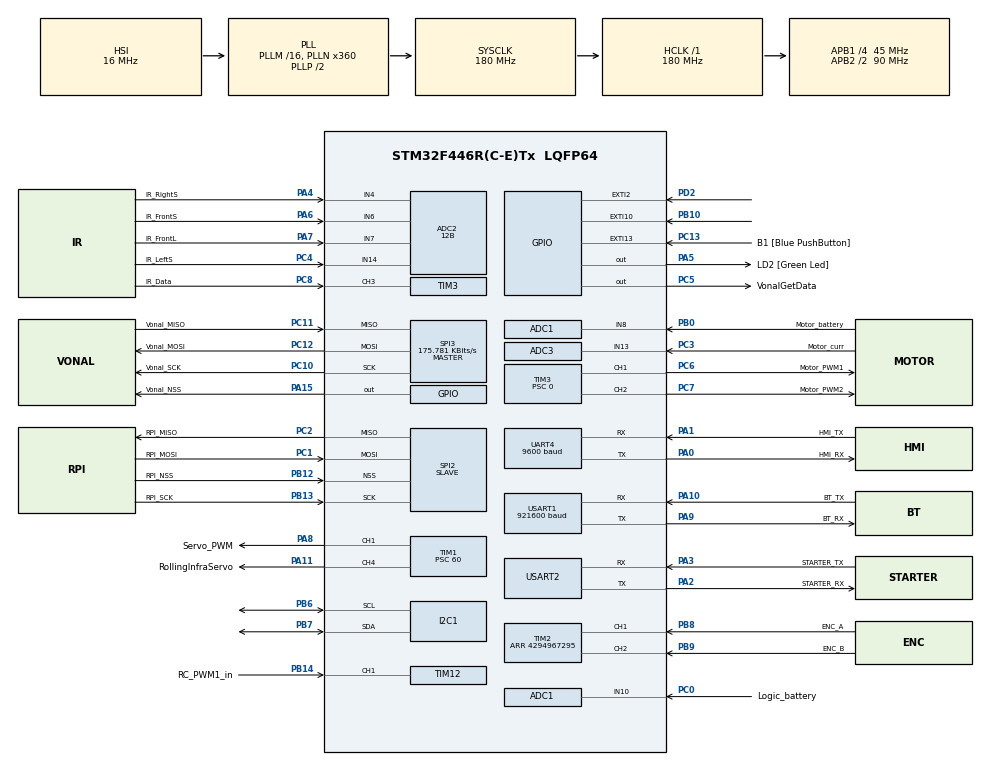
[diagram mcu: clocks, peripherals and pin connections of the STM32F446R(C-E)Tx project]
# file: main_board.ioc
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ADC1.Channel-0\#ChannelRegularConversion=ADC_CHANNEL_8
ADC1.Channel-1\#ChannelRegularConversion=ADC_CHANNEL_10
ADC1.Channel-2\#ChannelRegularConversion=ADC_CHANNEL_TEMPSENSOR
ADC1.ClockPrescaler=ADC_CLOCK_SYNC_PCLK_DIV8
ADC1.ContinuousConvMode=DISABLE
ADC1.DMAContinuousRequests=ENABLE
ADC1.DataAlign=ADC_DATAALIGN_RIGHT
ADC1.DiscontinuousConvMode=DISABLE
ADC1.EOCSelection=ADC_EOC_SINGLE_CONV
ADC1.EnableAnalogWatchDog=false
ADC1.ExternalTrigConv=ADC_SOFTWARE_START
ADC1.ExternalTrigConvEdge=ADC_EXTERNALTRIGCONVEDGE_NONE
ADC1.InjNumberOfConversion=0
ADC1.NbrOfConversion=3
ADC1.NbrOfConversionFlag=1
ADC1.Rank-0\#ChannelRegularConversion=1
ADC1.Rank-1\#ChannelRegularConversion=2
ADC1.Rank-2\#ChannelRegularConversion=3
ADC1.Resolution=ADC_RESOLUTION_12B
ADC1.SamplingTime-0\#ChannelRegularConversion=ADC_SAMPLETIME_480CYCLES
ADC1.SamplingTime-1\#ChannelRegularConversion=ADC_SAMPLETIME_480CYCLES
ADC1.SamplingTime-2\#ChannelRegularConversion=ADC_SAMPLETIME_480CYCLES
ADC1.ScanConvMode=ENABLE
ADC1.master=1
ADC2.Channel-0\#ChannelRegularConversion=ADC_CHANNEL_4
ADC2.Channel-1\#ChannelRegularConversion=ADC_CHANNEL_4
ADC2.Channel-2\#ChannelRegularConversion=ADC_CHANNEL_4
ADC2.Channel-3\#ChannelRegularConversion=ADC_CHANNEL_4
ADC2.Channel-4\#ChannelRegularConversion=ADC_CHANNEL_6
ADC2.Channel-5\#ChannelRegularConversion=ADC_CHANNEL_7
ADC2.Channel-6\#ChannelRegularConversion=ADC_CHANNEL_14
ADC2.ClockPrescaler=ADC_CLOCK_SYNC_PCLK_DIV8
ADC2.ContinuousConvMode=DISABLE
ADC2.DMAContinuousRequests=ENABLE
ADC2.DataAlign=ADC_DATAALIGN_RIGHT
ADC2.DiscontinuousConvMode=DISABLE
ADC2.EOCSelection=ADC_EOC_SINGLE_CONV
ADC2.EnableAnalogWatchDog=false
ADC2.ExternalTrigConv=ADC_SOFTWARE_START
ADC2.ExternalTrigConvEdge=ADC_EXTERNALTRIGCONVEDGE_NONE
ADC2.InjNumberOfConversion=0
ADC2.NbrOfConversion=4
ADC2.NbrOfConversionFlag=1
ADC2.Rank-0\#ChannelRegularConversion=1
ADC2.Rank-1\#ChannelRegularConversion=2
ADC2.Rank-2\#ChannelRegularConversion=3
ADC2.Rank-3\#ChannelRegularConversion=4
ADC2.Rank-4\#ChannelRegularConversion=2
ADC2.Rank-5\#ChannelRegularConversion=3
ADC2.Rank-6\#ChannelRegularConversion=4
ADC2.Resolution=ADC_RESOLUTION_12B
ADC2.SamplingTime-0\#ChannelRegularConversion=ADC_SAMPLETIME_480CYCLES
ADC2.SamplingTime-1\#ChannelRegularConversion=ADC_SAMPLETIME_3CYCLES
ADC2.SamplingTime-2\#ChannelRegularConversion=ADC_SAMPLETIME_3CYCLES
ADC2.SamplingTime-3\#ChannelRegularConversion=ADC_SAMPLETIME_3CYCLES
ADC2.SamplingTime-4\#ChannelRegularConversion=ADC_SAMPLETIME_480CYCLES
ADC2.SamplingTime-5\#ChannelRegularConversion=ADC_SAMPLETIME_480CYCLES
ADC2.SamplingTime-6\#ChannelRegularConversion=ADC_SAMPLETIME_480CYCLES
ADC2.ScanConvMode=ENABLE
ADC3.Channel-65\#ChannelRegularConversion=ADC_CHANNEL_13
ADC3.ClockPrescaler=ADC_CLOCK_SYNC_PCLK_DIV8
ADC3.ContinuousConvMode=DISABLE
ADC3.DMAContinuousRequests=ENABLE
ADC3.DataAlign=ADC_DATAALIGN_RIGHT
ADC3.DiscontinuousConvMode=DISABLE
ADC3.EOCSelection=ADC_EOC_SINGLE_CONV
ADC3.EnableAnalogWatchDog=false
ADC3.ExternalTrigConv=ADC_SOFTWARE_START
ADC3.ExternalTrigConvEdge=ADC_EXTERNALTRIGCONVEDGE_NONE
ADC3.InjNumberOfConversion=0
ADC3.NbrOfConversion=1
ADC3.NbrOfConversionFlag=1
ADC3.Rank-65\#ChannelRegularConversion=1
ADC3.Resolution=ADC_RESOLUTION_12B
ADC3.SamplingTime-65\#ChannelRegularConversion=ADC_SAMPLETIME_480CYCLES
ADC3.ScanConvMode=ENABLE
Dma.ADC1.11.Direction=DMA_PERIPH_TO_MEMORY
Dma.ADC1.11.FIFOMode=DMA_FIFOMODE_DISABLE
Dma.ADC1.11.Instance=DMA2_Stream0
Dma.ADC1.11.MemDataAlignment=DMA_MDATAALIGN_HALFWORD
Dma.ADC1.11.MemInc=DMA_MINC_ENABLE
Dma.ADC1.11.Mode=DMA_NORMAL
Dma.ADC1.11.PeriphDataAlignment=DMA_PDATAALIGN_HALFWORD
Dma.ADC1.11.PeriphInc=DMA_PINC_DISABLE
Dma.ADC1.11.Priority=DMA_PRIORITY_LOW
Dma.ADC2.4.Direction=DMA_PERIPH_TO_MEMORY
Dma.ADC2.4.FIFOMode=DMA_FIFOMODE_DISABLE
Dma.ADC2.4.Instance=DMA2_Stream2
Dma.ADC2.4.MemDataAlignment=DMA_MDATAALIGN_HALFWORD
Dma.ADC2.4.MemInc=DMA_MINC_ENABLE
Dma.ADC2.4.Mode=DMA_NORMAL
Dma.ADC2.4.PeriphDataAlignment=DMA_PDATAALIGN_HALFWORD
Dma.ADC2.4.PeriphInc=DMA_PINC_DISABLE
Dma.ADC2.4.Priority=DMA_PRIORITY_MEDIUM
Dma.ADC3.3.Direction=DMA_PERIPH_TO_MEMORY
Dma.ADC3.3.FIFOMode=DMA_FIFOMODE_DISABLE
Dma.ADC3.3.Instance=DMA2_Stream1
Dma.ADC3.3.MemDataAlignment=DMA_MDATAALIGN_HALFWORD
Dma.ADC3.3.MemInc=DMA_MINC_ENABLE
Dma.ADC3.3.Mode=DMA_NORMAL
Dma.ADC3.3.PeriphDataAlignment=DMA_PDATAALIGN_HALFWORD
Dma.ADC3.3.PeriphInc=DMA_PINC_DISABLE
Dma.ADC3.3.Priority=DMA_PRIORITY_HIGH
Dma.I2C1_RX.7.Direction=DMA_PERIPH_TO_MEMORY
Dma.I2C1_RX.7.FIFOMode=DMA_FIFOMODE_DISABLE
Dma.I2C1_RX.7.Instance=DMA1_Stream0
Dma.I2C1_RX.7.MemDataAlignment=DMA_MDATAALIGN_BYTE
Dma.I2C1_RX.7.MemInc=DMA_MINC_ENABLE
Dma.I2C1_RX.7.Mode=DMA_NORMAL
Dma.I2C1_RX.7.PeriphDataAlignment=DMA_PDATAALIGN_BYTE
Dma.I2C1_RX.7.PeriphInc=DMA_PINC_DISABLE
Dma.I2C1_RX.7.Priority=DMA_PRIORITY_LOW
Dma.I2C1_TX.8.Direction=DMA_MEMORY_TO_PERIPH
Dma.I2C1_TX.8.FIFOMode=DMA_FIFOMODE_DISABLE
Dma.I2C1_TX.8.Instance=DMA1_Stream6
Dma.I2C1_TX.8.MemDataAlignment=DMA_MDATAALIGN_BYTE
Dma.I2C1_TX.8.MemInc=DMA_MINC_ENABLE
Dma.I2C1_TX.8.Mode=DMA_NORMAL
Dma.I2C1_TX.8.PeriphDataAlignment=DMA_PDATAALIGN_BYTE
Dma.I2C1_TX.8.PeriphInc=DMA_PINC_DISABLE
Dma.I2C1_TX.8.Priority=DMA_PRIORITY_LOW
Dma.Request0=USART1_RX
Dma.Request1=USART1_TX
Dma.Request10=TIM3_CH1/TRIG
Dma.Request11=ADC1
Dma.Request12=SPI2_RX
Dma.Request2=TIM1_CH1
Dma.Request3=ADC3
Dma.Request4=ADC2
Dma.Request5=SPI3_RX
Dma.Request6=SPI3_TX
Dma.Request7=I2C1_RX
Dma.Request8=I2C1_TX
Dma.Request9=TIM3_CH2
Dma.SPI2_RX.12.Direction=DMA_PERIPH_TO_MEMORY
Dma.SPI2_RX.12.FIFOMode=DMA_FIFOMODE_ENABLE
Dma.SPI2_RX.12.FIFOThreshold=DMA_FIFO_THRESHOLD_3QUARTERSFULL
Dma.SPI2_RX.12.Instance=DMA1_Stream3
Dma.SPI2_RX.12.MemBurst=DMA_MBURST_SINGLE
Dma.SPI2_RX.12.MemDataAlignment=DMA_MDATAALIGN_BYTE
Dma.SPI2_RX.12.MemInc=DMA_MINC_ENABLE
Dma.SPI2_RX.12.Mode=DMA_NORMAL
Dma.SPI2_RX.12.PeriphBurst=DMA_PBURST_SINGLE
Dma.SPI2_RX.12.PeriphDataAlignment=DMA_PDATAALIGN_BYTE
Dma.SPI2_RX.12.PeriphInc=DMA_PINC_DISABLE
Dma.SPI2_RX.12.Priority=DMA_PRIORITY_LOW
Dma.SPI3_RX.5.Direction=DMA_PERIPH_TO_MEMORY
Dma.SPI3_RX.5.FIFOMode=DMA_FIFOMODE_DISABLE
Dma.SPI3_RX.5.Instance=DMA1_Stream2
Dma.SPI3_RX.5.MemDataAlignment=DMA_MDATAALIGN_BYTE
Dma.SPI3_RX.5.MemInc=DMA_MINC_ENABLE
Dma.SPI3_RX.5.Mode=DMA_NORMAL
Dma.SPI3_RX.5.PeriphDataAlignment=DMA_PDATAALIGN_BYTE
Dma.SPI3_RX.5.PeriphInc=DMA_PINC_DISABLE
Dma.SPI3_RX.5.Priority=DMA_PRIORITY_LOW
Dma.SPI3_TX.6.Direction=DMA_MEMORY_TO_PERIPH
Dma.SPI3_TX.6.FIFOMode=DMA_FIFOMODE_DISABLE
Dma.SPI3_TX.6.Instance=DMA1_Stream7
Dma.SPI3_TX.6.MemDataAlignment=DMA_MDATAALIGN_BYTE
Dma.SPI3_TX.6.MemInc=DMA_MINC_ENABLE
Dma.SPI3_TX.6.Mode=DMA_NORMAL
Dma.SPI3_TX.6.PeriphDataAlignment=DMA_PDATAALIGN_BYTE
Dma.SPI3_TX.6.PeriphInc=DMA_PINC_DISABLE
Dma.SPI3_TX.6.Priority=DMA_PRIORITY_LOW
Dma.TIM1_CH1.2.Direction=DMA_PERIPH_TO_MEMORY
Dma.TIM1_CH1.2.FIFOMode=DMA_FIFOMODE_DISABLE
Dma.TIM1_CH1.2.Instance=DMA2_Stream3
Dma.TIM1_CH1.2.MemDataAlignment=DMA_MDATAALIGN_HALFWORD
Dma.TIM1_CH1.2.MemInc=DMA_MINC_DISABLE
Dma.TIM1_CH1.2.Mode=DMA_NORMAL
Dma.TIM1_CH1.2.PeriphDataAlignment=DMA_PDATAALIGN_HALFWORD
Dma.TIM1_CH1.2.PeriphInc=DMA_PINC_DISABLE
Dma.TIM1_CH1.2.Priority=DMA_PRIORITY_LOW
Dma.TIM3_CH1/TRIG.10.Direction=DMA_PERIPH_TO_MEMORY
Dma.TIM3_CH1/TRIG.10.FIFOMode=DMA_FIFOMODE_DISABLE
Dma.TIM3_CH1/TRIG.10.Instance=DMA1_Stream4
Dma.TIM3_CH1/TRIG.10.MemDataAlignment=DMA_MDATAALIGN_HALFWORD
Dma.TIM3_CH1/TRIG.10.MemInc=DMA_MINC_ENABLE
Dma.TIM3_CH1/TRIG.10.Mode=DMA_NORMAL
Dma.TIM3_CH1/TRIG.10.PeriphDataAlignment=DMA_PDATAALIGN_HALFWORD
Dma.TIM3_CH1/TRIG.10.PeriphInc=DMA_PINC_DISABLE
Dma.TIM3_CH1/TRIG.10.Priority=DMA_PRIORITY_LOW
Dma.TIM3_CH2.9.Direction=DMA_PERIPH_TO_MEMORY
Dma.TIM3_CH2.9.FIFOMode=DMA_FIFOMODE_DISABLE
Dma.TIM3_CH2.9.Instance=DMA1_Stream5
Dma.TIM3_CH2.9.MemDataAlignment=DMA_MDATAALIGN_HALFWORD
Dma.TIM3_CH2.9.MemInc=DMA_MINC_ENABLE
Dma.TIM3_CH2.9.Mode=DMA_NORMAL
Dma.TIM3_CH2.9.PeriphDataAlignment=DMA_PDATAALIGN_HALFWORD
Dma.TIM3_CH2.9.PeriphInc=DMA_PINC_DISABLE
Dma.TIM3_CH2.9.Priority=DMA_PRIORITY_LOW
Dma.USART1_RX.0.Direction=DMA_PERIPH_TO_MEMORY
Dma.USART1_RX.0.FIFOMode=DMA_FIFOMODE_DISABLE
Dma.USART1_RX.0.Instance=DMA2_Stream5
Dma.USART1_RX.0.MemDataAlignment=DMA_MDATAALIGN_BYTE
Dma.USART1_RX.0.MemInc=DMA_MINC_ENABLE
Dma.USART1_RX.0.Mode=DMA_NORMAL
Dma.USART1_RX.0.PeriphDataAlignment=DMA_PDATAALIGN_BYTE
Dma.USART1_RX.0.PeriphInc=DMA_PINC_DISABLE
Dma.USART1_RX.0.Priority=DMA_PRIORITY_HIGH
Dma.USART1_TX.1.Direction=DMA_MEMORY_TO_PERIPH
Dma.USART1_TX.1.FIFOMode=DMA_FIFOMODE_DISABLE
Dma.USART1_TX.1.Instance=DMA2_Stream7
Dma.USART1_TX.1.MemDataAlignment=DMA_MDATAALIGN_BYTE
Dma.USART1_TX.1.MemInc=DMA_MINC_ENABLE
Dma.USART1_TX.1.Mode=DMA_NORMAL
Dma.USART1_TX.1.PeriphDataAlignment=DMA_PDATAALIGN_BYTE
Dma.USART1_TX.1.PeriphInc=DMA_PINC_DISABLE
Dma.USART1_TX.1.Priority=DMA_PRIORITY_HIGH
FREERTOS.INCLUDE_xEventGroupSetBitFromISR=1
FREERTOS.INCLUDE_xTimerPendFunctionCall=1
FREERTOS.Tasks01=defaultTask,0,128,StartDefaultTask,Default,NULL
FREERTOS.configTOTAL_HEAP_SIZE=100000
FREERTOS.configUSE_TIMERS=1
Mcu.Family=STM32F4
Mcu.Name=STM32F446R(C-E)Tx
Mcu.Package=LQFP64
NVIC.ADC_IRQn=true\:5\:0\:false\:false\:true\:true\:true
NVIC.DMA1_Stream0_IRQn=true\:5\:0\:false\:false\:true\:true\:false
NVIC.DMA1_Stream2_IRQn=true\:5\:0\:false\:false\:true\:false\:false
NVIC.DMA1_Stream3_IRQn=true\:5\:0\:false\:false\:true\:true\:false
NVIC.DMA1_Stream4_IRQn=true\:5\:0\:false\:false\:true\:true\:false
NVIC.DMA1_Stream5_IRQn=true\:5\:0\:false\:false\:true\:true\:false
NVIC.DMA1_Stream6_IRQn=true\:5\:0\:false\:false\:true\:true\:false
NVIC.DMA1_Stream7_IRQn=true\:5\:0\:false\:false\:true\:true\:false
NVIC.DMA2_Stream0_IRQn=true\:5\:0\:false\:false\:true\:true\:false
NVIC.DMA2_Stream1_IRQn=true\:5\:0\:false\:false\:true\:true\:false
NVIC.DMA2_Stream2_IRQn=true\:5\:0\:false\:false\:true\:true\:false
NVIC.DMA2_Stream3_IRQn=true\:5\:0\:false\:false\:true\:true\:false
NVIC.DMA2_Stream5_IRQn=true\:5\:0\:false\:false\:true\:true\:false
NVIC.DMA2_Stream7_IRQn=true\:5\:0\:false\:false\:true\:true\:false
NVIC.EXTI15_10_IRQn=true\:5\:0\:false\:false\:true\:true\:true
NVIC.EXTI2_IRQn=true\:5\:0\:false\:false\:true\:true\:true
NVIC.I2C1_ER_IRQn=true\:5\:0\:false\:false\:true\:true\:true
NVIC.I2C1_EV_IRQn=true\:5\:0\:false\:false\:true\:true\:true
NVIC.PriorityGroup=NVIC_PRIORITYGROUP_4
NVIC.SPI2_IRQn=true\:5\:0\:false\:false\:true\:true\:true
NVIC.SPI3_IRQn=true\:5\:0\:false\:false\:true\:true\:true
NVIC.TIM8_BRK_TIM12_IRQn=true\:5\:0\:false\:false\:true\:true\:true
NVIC.TIM8_TRG_COM_TIM14_IRQn=true\:0\:0\:false\:false\:true\:false\:true
NVIC.TimeBase=TIM8_TRG_COM_TIM14_IRQn
NVIC.TimeBaseIP=TIM14
NVIC.UART4_IRQn=true\:5\:0\:false\:false\:true\:true\:true
NVIC.USART1_IRQn=true\:5\:0\:false\:false\:true\:true\:true
NVIC.USART2_IRQn=true\:5\:0\:false\:false\:true\:true\:true
PA0-WKUP.GPIO_Label=HMI_RX
PA0-WKUP.Mode=Asynchronous
PA0-WKUP.Signal=UART4_TX
PA1.GPIO_Label=HMI_TX
PA1.Mode=Asynchronous
PA1.Signal=UART4_RX
PA10.GPIO_Label=BT_TX
PA10.Mode=Asynchronous
PA10.Signal=USART1_RX
PA11.GPIO_Label=RollingInfraServo
PA11.Signal=S_TIM1_CH4
PA13.GPIO_Label=TMS
PA13.Signal=SYS_JTMS-SWDIO
PA14.GPIO_Label=TCK
PA14.Signal=SYS_JTCK-SWCLK
PA15.GPIO_Label=Vonal_NSS
PA15.GPIO_Speed=GPIO_SPEED_FREQ_VERY_HIGH
PA15.PinState=GPIO_PIN_SET
PA15.Signal=GPIO_Output
PA2.GPIO_Label=STARTER_RX
PA2.Mode=Asynchronous
PA2.Signal=USART2_TX
PA3.GPIO_Label=STARTER_TX
PA3.Mode=Asynchronous
PA3.Signal=USART2_RX
PA4.GPIO_Label=IR_RightS
PA4.Signal=ADCx_IN4
PA5.GPIO_Label=LD2 [Green Led]
PA5.Signal=GPIO_Output
PA6.GPIO_Label=IR_FrontS
PA6.Signal=ADCx_IN6
PA7.GPIO_Label=IR_FrontL
PA7.Signal=ADCx_IN7
PA8.GPIO_Label=Servo_PWM
PA8.GPIO_Speed=GPIO_SPEED_FREQ_HIGH
PA8.Signal=S_TIM1_CH1
PA9.GPIO_Label=BT_RX
PA9.Mode=Asynchronous
PA9.Signal=USART1_TX
PB0.GPIO_Label=Motor_battery
PB0.Signal=ADCx_IN8
PB10.Signal=GPXTI10
PB12.GPIO_Label=RPI_NSS
PB12.Mode=NSS_Signal_Hard_Input
PB12.Signal=SPI2_NSS
PB13.GPIO_Label=RPI_SCK
PB13.Mode=Full_Duplex_Slave
PB13.Signal=SPI2_SCK
PB14.GPIO_Label=RC_PWM1_in
PB14.Signal=S_TIM12_CH1
PB3.GPIO_Label=SWO
PB3.Signal=SYS_JTDO-SWO
PB6.Mode=I2C
PB6.Signal=I2C1_SCL
PB7.Mode=I2C
PB7.Signal=I2C1_SDA
PB8.GPIO_Label=ENC_A
PB8.GPIO_PuPd=GPIO_NOPULL
PB8.Signal=S_TIM2_CH1_ETR
PB9.GPIO_Label=ENC_B
PB9.GPIO_PuPd=GPIO_NOPULL
PB9.Signal=S_TIM2_CH2
PC0.GPIO_Label=Logic_battery
PC0.Signal=ADCx_IN10
PC1.GPIO_Label=RPI_MOSI
PC1.Mode=Full_Duplex_Slave
PC1.Signal=SPI2_MOSI
PC10.GPIO_Label=Vonal_SCK
PC10.GPIO_PuPd=GPIO_PULLDOWN
PC10.Mode=Full_Duplex_Master
PC10.Signal=SPI3_SCK
PC11.GPIO_Label=Vonal_MISO
PC11.Mode=Full_Duplex_Master
PC11.Signal=SPI3_MISO
PC12.GPIO_Label=Vonal_MOSI
PC12.Mode=Full_Duplex_Master
PC12.Signal=SPI3_MOSI
PC13.GPIO_Label=B1 [Blue PushButton]
PC13.GPIO_ModeDefaultEXTI=GPIO_MODE_IT_FALLING
PC13.Signal=GPXTI13
PC14-OSC32_IN.Signal=RCC_OSC32_IN
PC15-OSC32_OUT.Signal=RCC_OSC32_OUT
PC2.GPIO_Label=RPI_MISO
PC2.Mode=Full_Duplex_Slave
PC2.Signal=SPI2_MISO
PC3.GPIO_Label=Motor_curr
PC3.Signal=ADCx_IN13
PC4.GPIO_Label=IR_LeftS
PC4.Signal=ADCx_IN14
PC5.GPIO_Label=VonalGetData
PC5.Signal=GPIO_Output
PC6.GPIO_Label=Motor_PWM1
PC6.Signal=S_TIM3_CH1
PC7.GPIO_Label=Motor_PWM2
PC7.Signal=S_TIM3_CH2
PC8.GPIO_Label=IR_Data
PC8.Signal=S_TIM3_CH3
PD2.Signal=GPXTI2
PH0-OSC_IN.Signal=RCC_OSC_IN
PH1-OSC_OUT.Signal=RCC_OSC_OUT
ProjectManager.HeapSize=0x200
ProjectManager.StackSize=0x400
ProjectManager.TargetToolchain=TrueSTUDIO
RCC.AHBFreq_Value=180000000
RCC.APB1CLKDivider=RCC_HCLK_DIV4
RCC.APB1Freq_Value=45000000
RCC.APB1TimFreq_Value=90000000
RCC.APB2CLKDivider=RCC_HCLK_DIV2
RCC.APB2Freq_Value=90000000
RCC.APB2TimFreq_Value=180000000
RCC.CortexFreq_Value=180000000
RCC.FLatency-AdvancedSettings=FLASH_LATENCY_5
RCC.HCLKFreq_Value=180000000
RCC.HSE_VALUE=8000000
RCC.HSI_VALUE=16000000
RCC.LSE_VALUE=32768
RCC.PLLN=360
RCC.SYSCLKFreq_VALUE=180000000
RCC.SYSCLKSource=RCC_SYSCLKSOURCE_PLLCLK
RCC.USBFreq_Value=180000000
RCC.VCOOutputFreq_Value=360000000
SH.ADCx_IN10.0=ADC1_IN10,IN10
SH.ADCx_IN13.0=ADC3_IN13,IN13
SH.ADCx_IN14.0=ADC2_IN14,IN14
SH.ADCx_IN4.0=ADC2_IN4,IN4
SH.ADCx_IN6.0=ADC2_IN6,IN6
SH.ADCx_IN7.0=ADC2_IN7,IN7
SH.ADCx_IN8.0=ADC1_IN8,IN8
SH.S_TIM12_CH1.0=TIM12_CH1,PWM_Input_1
SH.S_TIM1_CH1.0=TIM1_CH1,PWM Generation1 CH1
SH.S_TIM1_CH4.0=TIM1_CH4,PWM Generation4 CH4
SH.S_TIM2_CH1_ETR.0=TIM2_CH1,Encoder_Interface
SH.S_TIM2_CH2.0=TIM2_CH2,Encoder_Interface
SH.S_TIM3_CH1.0=TIM3_CH1,PWM Generation1 CH1
SH.S_TIM3_CH2.0=TIM3_CH2,PWM Generation2 CH2
SH.S_TIM3_CH3.0=TIM3_CH3,Input_Capture3_from_TI3
SPI2.Direction=SPI_DIRECTION_2LINES
SPI2.Mode=SPI_MODE_SLAVE
SPI2.VirtualNSS=VM_NSSHARD
SPI2.VirtualType=VM_SLAVE
SPI3.BaudRatePrescaler=SPI_BAUDRATEPRESCALER_256
SPI3.CLKPhase=SPI_PHASE_1EDGE
SPI3.CalculateBaudRate=175.781 KBits/s
SPI3.Direction=SPI_DIRECTION_2LINES
SPI3.Mode=SPI_MODE_MASTER
SPI3.VirtualType=VM_MASTER
TIM1.Channel-PWM\ Generation1\ CH1=TIM_CHANNEL_1
TIM1.Channel-PWM\ Generation4\ CH4=TIM_CHANNEL_4
TIM1.ClockDivision=TIM_CLOCKDIVISION_DIV1
TIM1.CounterMode=TIM_COUNTERMODE_DOWN
TIM1.OCIdleState_1=TIM_OCIDLESTATE_RESET
TIM1.OCMode_PWM-PWM\ Generation1\ CH1=TIM_OCMODE_PWM1
TIM1.OCPolarity_1=TIM_OCPOLARITY_HIGH
TIM1.Period=60000
TIM1.Prescaler=60
TIM1.Pulse-PWM\ Generation1\ CH1=4180
TIM1.Pulse-PWM\ Generation4\ CH4=4180
TIM12.Period=65535
TIM12.Prescaler=100
TIM2.ClockDivision=TIM_CLOCKDIVISION_DIV1
TIM2.EncoderMode=TIM_ENCODERMODE_TI12
TIM2.IC1Polarity=TIM_ICPOLARITY_FALLING
TIM2.IC2Polarity=TIM_ICPOLARITY_RISING
TIM2.Period=4294967295
TIM3.Channel-Input_Capture3_from_TI3=TIM_CHANNEL_3
TIM3.Channel-PWM\ Generation1\ CH1=TIM_CHANNEL_1
TIM3.Channel-PWM\ Generation2\ CH2=TIM_CHANNEL_2
TIM3.CounterMode=TIM_COUNTERMODE_CENTERALIGNED1
TIM3.OCPolarity_2=TIM_OCPOLARITY_HIGH
TIM3.Period=4500
TIM3.Prescaler=0
TIM3.Pulse-PWM\ Generation1\ CH1=2250
TIM3.Pulse-PWM\ Generation2\ CH2=2250
UART4.BaudRate=9600
UART4.VirtualMode=Asynchronous
USART1.BaudRate=921600
USART1.VirtualMode=VM_ASYNC
USART2.VirtualMode=VM_ASYNC
VP_ADC1_TempSens_Input.Mode=IN-TempSens
VP_FREERTOS_VS_ENABLE.Mode=Enabled
VP_SYS_VS_tim14.Mode=TIM14
VP_TIM10_VS_ClockSourceINT.Mode=Enable_Timer
VP_TIM1_VS_ClockSourceINT.Mode=Internal
VP_TIM7_VS_ClockSourceINT.Mode=Enable_Timer
board=NUCLEO-F446RE

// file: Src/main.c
/**
  ******************************************************************************
  * File Name          : main.c
  * Description        : Main program body
  ******************************************************************************
  * This notice applies to any and all portions of this file
  * that are not between comment pairs USER CODE BEGIN and
  * USER CODE END. Other portions of this file, whether
  * inserted by the user or by software development tools
  * are owned by their respective copyright owners.
  *
  * Copyright (c) 2018 STMicroelectronics International N.V.
  * All rights reserved.
  *
  * Redistribution and use in source and binary forms, with or without
  * modification, are permitted, provided that the following conditions are met:
  *
  * 1. Redistribution of source code must retain the above copyright notice,
  *    this list of conditions and the following disclaimer.
  * 2. Redistributions in binary form must reproduce the above copyright notice,
  *    this list of conditions and the following disclaimer in the documentation
  *    and/or other materials provided with the distribution.
  * 3. Neither the name of STMicroelectronics nor the names of other
  *    contributors to this software may be used to endorse or promote products
  *    derived from this software without specific written permission.
  * 4. This software, including modifications and/or derivative works of this
  *    software, must execute solely and exclusively on microcontroller or
  *    microprocessor devices manufactured by or for STMicroelectronics.
  * 5. Redistribution and use of this software other than as permitted under
  *    this license is void and will automatically terminate your rights under
  *    this license.
  *
  * THIS SOFTWARE IS PROVIDED BY STMICROELECTRONICS AND CONTRIBUTORS "AS IS"
  * AND ANY EXPRESS, IMPLIED OR STATUTORY WARRANTIES, INCLUDING, BUT NOT
  * LIMITED TO, THE IMPLIED WARRANTIES OF MERCHANTABILITY, FITNESS FOR A
  * PARTICULAR PURPOSE AND NON-INFRINGEMENT OF THIRD PARTY INTELLECTUAL PROPERTY
  * RIGHTS ARE DISCLAIMED TO THE FULLEST EXTENT PERMITTED BY LAW. IN NO EVENT
  * SHALL STMICROELECTRONICS OR CONTRIBUTORS BE LIABLE FOR ANY DIRECT, INDIRECT,
  * INCIDENTAL, SPECIAL, EXEMPLARY, OR CONSEQUENTIAL DAMAGES (INCLUDING, BUT NOT
  * LIMITED TO, PROCUREMENT OF SUBSTITUTE GOODS OR SERVICES; LOSS OF USE, DATA,
  * OR PROFITS; OR BUSINESS INTERRUPTION) HOWEVER CAUSED AND ON ANY THEORY OF
  * LIABILITY, WHETHER IN CONTRACT, STRICT LIABILITY, OR TORT (INCLUDING
  * NEGLIGENCE OR OTHERWISE) ARISING IN ANY WAY OUT OF THE USE OF THIS SOFTWARE,
  * EVEN IF ADVISED OF THE POSSIBILITY OF SUCH DAMAGE.
  *
  ******************************************************************************
  */

#include "main.h"
#include "stm32f4xx_hal.h"
#include "cmsis_os.h"

/* USER CODE BEGIN Includes */

#include "register_map.h"
#include "bluetooth.h"
#include "hmi.h"
#include "ir.h"
#include "line_sensor.h"
#include "mpu6050.h"
#include "starter.h"
#include "string.h"
#include "controller.h"
#include "remotecontrol.h"
#include "statemachine.h"
#include "rpi.h"

/* USER CODE END Includes */

ADC_HandleTypeDef hadc1;
ADC_HandleTypeDef hadc2;
ADC_HandleTypeDef hadc3;
DMA_HandleTypeDef hdma_adc1;
DMA_HandleTypeDef hdma_adc2;
DMA_HandleTypeDef hdma_adc3;

I2C_HandleTypeDef hi2c1;
DMA_HandleTypeDef hdma_i2c1_rx;
DMA_HandleTypeDef hdma_i2c1_tx;

SPI_HandleTypeDef hspi2;
SPI_HandleTypeDef hspi3;
DMA_HandleTypeDef hdma_spi2_rx;
DMA_HandleTypeDef hdma_spi3_rx;
DMA_HandleTypeDef hdma_spi3_tx;

TIM_HandleTypeDef htim1;
TIM_HandleTypeDef htim2;
TIM_HandleTypeDef htim3;
TIM_HandleTypeDef htim7;
TIM_HandleTypeDef htim10;
TIM_HandleTypeDef htim12;
DMA_HandleTypeDef hdma_tim1_ch1;
DMA_HandleTypeDef hdma_tim3_ch2;
DMA_HandleTypeDef hdma_tim3_ch1_trig;

UART_HandleTypeDef huart4;
UART_HandleTypeDef huart1;
UART_HandleTypeDef huart2;
DMA_HandleTypeDef hdma_usart1_rx;
DMA_HandleTypeDef hdma_usart1_tx;

osThreadId defaultTaskHandle;

/* USER CODE BEGIN PV */
/* Private variables ---------------------------------------------------------*/

osThreadId SendBTTaskHandle;
osThreadId LineDataTaskHandle;
osThreadId InitTaskHandle;
osThreadId DetectTaskHandle;
osThreadId ControllerTaskHandle;
osThreadId RemotecontrolTaskHandle;
osThreadId CheckBatteriesTaskHandle;
osThreadId ReadDistanceSensorsTaskHandle;
osThreadId ReadMotorCurrentTaskHandle;
osThreadId InfraReceiveTaskHandle;
osThreadId ReadMEMSTaskHandle;
osThreadId StateMachineTaskHandle;
osThreadId SpeedControllerTaskHandle;
osThreadId UthosszTaskHandle;
osThreadId SteeringStateSpaceControllerHandle;
osThreadId ServoSetterTaskHandle;
osThreadId LineDetectorTaskHandle;
osThreadId RollAngleControllerTaskHandle;
osThreadId CarTrackerTaskHandle;
osThreadId HMITaskHandle;

SemaphoreHandle_t Semaphore_linesensor_ready;
SemaphoreHandle_t Semaphore_SPI_vonal_buffer;
SemaphoreHandle_t Semaphore_ADC_batteries;
SemaphoreHandle_t Semaphore_ADC_dist_sensors;
SemaphoreHandle_t Semaphore_ADC_motor_curr;
SemaphoreHandle_t Semaphore_MEMS_ready;
SemaphoreHandle_t Semaphore_Uthossz_Achieved;
EventGroupHandle_t Eventgroup_inputCaptures;
EventGroupHandle_t Eventgroup_Triggers;
TimerHandle_t xTimers[NUM_OF_TIMERS];

/* USER CODE END PV */

void SystemClock_Config(void);
static void MX_GPIO_Init(void);
static void MX_DMA_Init(void);
static void MX_ADC1_Init(void);
static void MX_ADC2_Init(void);
static void MX_ADC3_Init(void);
static void MX_SPI2_Init(void);
static void MX_SPI3_Init(void);
static void MX_TIM1_Init(void);
static void MX_TIM2_Init(void);
static void MX_TIM3_Init(void);
static void MX_TIM10_Init(void);
static void MX_TIM12_Init(void);
static void MX_UART4_Init(void);
static void MX_USART1_UART_Init(void);
static void MX_USART2_UART_Init(void);
static void MX_TIM7_Init(void);
static void MX_I2C1_Init(void);
void StartDefaultTask(void const * argument);

void HAL_TIM_MspPostInit(TIM_HandleTypeDef *htim);

/* USER CODE BEGIN PFP */
/* Private function prototypes -----------------------------------------------*/

void BTCommunicationTask(void const * argument);
void LineGetData(void const * argument);
void InitTask(void const * argument);
void DetectTask(void const * argument);
void CheckBatteriesTask(void const * argument);
void ReadDistanceSensorsTask(void const * argument);
void ReadMotorCurrentTask(void const * argument);
void InfraReceiveTask(void const * argument);
void ReadMEMSTask(void const * argument);
void StateMachineTask(void const * argument);
void SpeedControllerTask (void const * argument);
void UthosszTask(void const * argument);
void SteeringStateSpaceController(void const * argument);
void PIDController(void const * argument);
void ServoSetterTask(void const * argument);
void LineDetectorTask(void const * argument);
void RollAngleControllerTask(void const * argument);
void CarTrackerTask();
void HMITask();

/* USER CODE END PFP */

int main(void)
{

  /* USER CODE BEGIN 1 */
	InitRegisters();
  /* USER CODE END 1 */

  /* MCU Configuration----------------------------------------------------------*/

  /* Reset of all peripherals, Initializes the Flash interface and the Systick. */
  HAL_Init();

  /* Configure the system clock */
  SystemClock_Config();

  /* Initialize all configured peripherals */
  MX_GPIO_Init();
  MX_DMA_Init();
  MX_ADC1_Init();
  MX_ADC2_Init();
  MX_ADC3_Init();
  MX_SPI2_Init();
  MX_SPI3_Init();
  MX_TIM1_Init();
  MX_TIM2_Init();
  MX_TIM3_Init();
  MX_TIM10_Init();
  MX_TIM12_Init();
  MX_UART4_Init();
  MX_USART1_UART_Init();
  MX_USART2_UART_Init();
  MX_TIM7_Init();
  MX_I2C1_Init();

  /* Create the thread(s) */
  /* definition and creation of defaultTask */
  osThreadDef(defaultTask, StartDefaultTask, osPriorityNormal, 0, 128);
  defaultTaskHandle = osThreadCreate(osThread(defaultTask), NULL);

  /* USER CODE BEGIN RTOS_THREADS */
  /* add threads, ... */
  osThreadDef(BTCom, BTCommunicationTask, osPriorityBelowNormal, 0, 512);
  SendBTTaskHandle = osThreadCreate(osThread(BTCom), NULL);

  osThreadDef(Init, InitTask, osPriorityNormal, 0, 128);
  InitTaskHandle = osThreadCreate(osThread(Init), NULL);

  osThreadDef(LineDataTask, LineGetData, osPriorityHigh, 0, 512);
  LineDataTaskHandle = osThreadCreate(osThread(LineDataTask), NULL);

  osThreadDef(ControllerTask, PIDController, osPriorityNormal, 0, 512);
  ControllerTaskHandle = osThreadCreate(osThread(ControllerTask), NULL);

  osThreadDef(DetectTask, DetectTask, osPriorityNormal, 0, 512);
  DetectTaskHandle = osThreadCreate(osThread(DetectTask), NULL);

  osThreadDef(RemotecontrolTask, RemoteControllerTask, osPriorityLow, 0, 128);
  RemotecontrolTaskHandle = osThreadCreate(osThread(RemotecontrolTask), NULL);

  osThreadDef(CheckBatteriesTask, CheckBatteriesTask, osPriorityLow, 0, 128);
  CheckBatteriesTaskHandle = osThreadCreate(osThread(CheckBatteriesTask), NULL);

  osThreadDef(ReadDistanceSensorsTask, ReadDistanceSensorsTask, osPriorityBelowNormal, 0, 512);
  ReadDistanceSensorsTaskHandle = osThreadCreate(osThread(ReadDistanceSensorsTask), NULL);

  osThreadDef(ReadMotorCurrentTask, ReadMotorCurrentTask, osPriorityLow, 0, 128);
  ReadMotorCurrentTaskHandle = osThreadCreate(osThread(ReadMotorCurrentTask), NULL);

  osThreadDef(InfraReceiveTask, InfraReceiveTask, osPriorityBelowNormal, 0, 256);
  InfraReceiveTaskHandle = osThreadCreate(osThread(InfraReceiveTask), NULL);

  //osThreadDef(ReadMEMSTask, ReadMEMSTask, osPriorityNormal, 0, 512);
  //ReadMEMSTaskHandle = osThreadCreate(osThread(ReadMEMSTask), NULL);

  osThreadDef(StateMachineTask, StateMachineTask, osPriorityNormal, 0, 512);
  StateMachineTaskHandle = osThreadCreate(osThread(StateMachineTask), NULL);

  osThreadDef(SpeedControllerTask, SpeedControllerTask, osPriorityAboveNormal, 0, 512);
  SpeedControllerTaskHandle = osThreadCreate(osThread(SpeedControllerTask), NULL);

  osThreadDef(UthosszTask, UthosszTask, osPriorityNormal, 0, 256);
  UthosszTaskHandle = osThreadCreate(osThread(UthosszTask), NULL);

  osThreadDef(SteeringStateSpaceController, SteeringStateSpaceController, osPriorityHigh, 0, 256);
  SteeringStateSpaceControllerHandle = osThreadCreate(osThread(SteeringStateSpaceController), NULL);

  osThreadDef(ServoSetterTask, ServoSetterTask, osPriorityHigh, 0, 128);
  ServoSetterTaskHandle = osThreadCreate(osThread(ServoSetterTask), NULL);

  osThreadDef(LineDetectorTask, LineDetectorTask, osPriorityAboveNormal, 0, 128);
  LineDetectorTaskHandle = osThreadCreate(osThread(LineDetectorTask), NULL);

  osThreadDef(RollAngleControllerTask, RollAngleControllerTask, osPriorityAboveNormal, 0, 128);
  RollAngleControllerTaskHandle = osThreadCreate(osThread(RollAngleControllerTask), NULL);

  osThreadDef(CarTrackerTask, CarTrackerTask, osPriorityAboveNormal, 0, 128);
  CarTrackerTaskHandle = osThreadCreate(osThread(CarTrackerTask), NULL);

  osThreadDef(HMITask, HMITask, osPriorityAboveNormal, 0, 128);
  HMITaskHandle = osThreadCreate(osThread(HMITask), NULL);

  osThreadSuspend(ServoSetterTaskHandle);
  osThreadSuspend(LineDataTaskHandle );
  osThreadSuspend(SendBTTaskHandle);
  osThreadSuspend(DetectTaskHandle);
  osThreadSuspend(defaultTaskHandle);
  osThreadSuspend(RemotecontrolTaskHandle);
  osThreadSuspend(CheckBatteriesTaskHandle);
  osThreadSuspend(ReadDistanceSensorsTaskHandle);
  osThreadSuspend(ReadMotorCurrentTaskHandle);
  osThreadSuspend(InfraReceiveTaskHandle);
  osThreadSuspend(ReadMEMSTaskHandle);
  osThreadSuspend(StateMachineTaskHandle);
  osThreadSuspend(SpeedControllerTaskHandle);
  osThreadSuspend(UthosszTaskHandle);
  osThreadSuspend(SteeringStateSpaceControllerHandle);
  osThreadSuspend(ControllerTaskHandle);
  osThreadSuspend(LineDetectorTaskHandle);
  osThreadSuspend(RollAngleControllerTaskHandle);
  osThreadSuspend(CarTrackerTaskHandle);
  osThreadSuspend(HMITaskHandle);

  InitTimers();

  /* USER CODE END RTOS_THREADS */

  /* Start scheduler */
  osKernelStart();

  /* We should never get here as control is now taken by the scheduler */

  /* Infinite loop */
  while (1)
  {

  }

}

/** System Clock Configuration
*/
void SystemClock_Config(void)
{

  RCC_OscInitTypeDef RCC_OscInitStruct;
  RCC_ClkInitTypeDef RCC_ClkInitStruct;

    /**Configure the main internal regulator output voltage
    */
  __HAL_RCC_PWR_CLK_ENABLE();

  __HAL_PWR_VOLTAGESCALING_CONFIG(PWR_REGULATOR_VOLTAGE_SCALE1);

    /**Initializes the CPU, AHB and APB busses clocks
    */
  RCC_OscInitStruct.OscillatorType = RCC_OSCILLATORTYPE_HSI;
  RCC_OscInitStruct.HSIState = RCC_HSI_ON;
  RCC_OscInitStruct.HSICalibrationValue = 16;
  RCC_OscInitStruct.PLL.PLLState = RCC_PLL_ON;
  RCC_OscInitStruct.PLL.PLLSource = RCC_PLLSOURCE_HSI;
  RCC_OscInitStruct.PLL.PLLM = 16;
  RCC_OscInitStruct.PLL.PLLN = 360;
  RCC_OscInitStruct.PLL.PLLP = RCC_PLLP_DIV2;
  RCC_OscInitStruct.PLL.PLLQ = 2;
  RCC_OscInitStruct.PLL.PLLR = 2;
  if (HAL_RCC_OscConfig(&RCC_OscInitStruct) != HAL_OK)
  {
    _Error_Handler(__FILE__, __LINE__);
  }

    /**Activate the Over-Drive mode
    */
  if (HAL_PWREx_EnableOverDrive() != HAL_OK)
  {
    _Error_Handler(__FILE__, __LINE__);
  }

    /**Initializes the CPU, AHB and APB busses clocks
    */
  RCC_ClkInitStruct.ClockType = RCC_CLOCKTYPE_HCLK|RCC_CLOCKTYPE_SYSCLK
                              |RCC_CLOCKTYPE_PCLK1|RCC_CLOCKTYPE_PCLK2;
  RCC_ClkInitStruct.SYSCLKSource = RCC_SYSCLKSOURCE_PLLCLK;
  RCC_ClkInitStruct.AHBCLKDivider = RCC_SYSCLK_DIV1;
  RCC_ClkInitStruct.APB1CLKDivider = RCC_HCLK_DIV4;
  RCC_ClkInitStruct.APB2CLKDivider = RCC_HCLK_DIV2;

  if (HAL_RCC_ClockConfig(&RCC_ClkInitStruct, FLASH_LATENCY_5) != HAL_OK)
  {
    _Error_Handler(__FILE__, __LINE__);
  }

    /**Configure the Systick interrupt time
    */
  HAL_SYSTICK_Config(HAL_RCC_GetHCLKFreq()/1000);

    /**Configure the Systick
    */
  HAL_SYSTICK_CLKSourceConfig(SYSTICK_CLKSOURCE_HCLK);

  /* SysTick_IRQn interrupt configuration */
  HAL_NVIC_SetPriority(SysTick_IRQn, 15, 0);
}

/* ADC1 init function */
static void MX_ADC1_Init(void)
{

  ADC_ChannelConfTypeDef sConfig;

    /**Configure the global features of the ADC (Clock, Resolution, Data Alignment and number of conversion)
    */
  hadc1.Instance = ADC1;
  hadc1.Init.ClockPrescaler = ADC_CLOCK_SYNC_PCLK_DIV8;
  hadc1.Init.Resolution = ADC_RESOLUTION_12B;
  hadc1.Init.ScanConvMode = ENABLE;
  hadc1.Init.ContinuousConvMode = DISABLE;
  hadc1.Init.DiscontinuousConvMode = DISABLE;
  hadc1.Init.ExternalTrigConvEdge = ADC_EXTERNALTRIGCONVEDGE_NONE;
  hadc1.Init.ExternalTrigConv = ADC_SOFTWARE_START;
  hadc1.Init.DataAlign = ADC_DATAALIGN_RIGHT;
  hadc1.Init.NbrOfConversion = 3;
  hadc1.Init.DMAContinuousRequests = ENABLE;
  hadc1.Init.EOCSelection = ADC_EOC_SINGLE_CONV;
  if (HAL_ADC_Init(&hadc1) != HAL_OK)
  {
    _Error_Handler(__FILE__, __LINE__);
  }

    /**Configure for the selected ADC regular channel its corresponding rank in the sequencer and its sample time.
    */
  sConfig.Channel = ADC_CHANNEL_8;
  sConfig.Rank = 1;
  sConfig.SamplingTime = ADC_SAMPLETIME_480CYCLES;
  if (HAL_ADC_ConfigChannel(&hadc1, &sConfig) != HAL_OK)
  {
    _Error_Handler(__FILE__, __LINE__);
  }

    /**Configure for the selected ADC regular channel its corresponding rank in the sequencer and its sample time.
    */
  sConfig.Channel = ADC_CHANNEL_10;
  sConfig.Rank = 2;
  if (HAL_ADC_ConfigChannel(&hadc1, &sConfig) != HAL_OK)
  {
    _Error_Handler(__FILE__, __LINE__);
  }

    /**Configure for the selected ADC regular channel its corresponding rank in the sequencer and its sample time.
    */
  sConfig.Channel = ADC_CHANNEL_TEMPSENSOR;
  sConfig.Rank = 3;
  if (HAL_ADC_ConfigChannel(&hadc1, &sConfig) != HAL_OK)
  {
    _Error_Handler(__FILE__, __LINE__);
  }

}

/* ADC2 init function */
static void MX_ADC2_Init(void)
{

  ADC_ChannelConfTypeDef sConfig;

    /**Configure the global features of the ADC (Clock, Resolution, Data Alignment and number of conversion)
    */
  hadc2.Instance = ADC2;
  hadc2.Init.ClockPrescaler = ADC_CLOCK_SYNC_PCLK_DIV8;
  hadc2.Init.Resolution = ADC_RESOLUTION_12B;
  hadc2.Init.ScanConvMode = ENABLE;
  hadc2.Init.ContinuousConvMode = DISABLE;
  hadc2.Init.DiscontinuousConvMode = DISABLE;
  hadc2.Init.ExternalTrigConvEdge = ADC_EXTERNALTRIGCONVEDGE_NONE;
  hadc2.Init.ExternalTrigConv = ADC_SOFTWARE_START;
  hadc2.Init.DataAlign = ADC_DATAALIGN_RIGHT;
  hadc2.Init.NbrOfConversion = 4;
  hadc2.Init.DMAContinuousRequests = ENABLE;
  hadc2.Init.EOCSelection = ADC_EOC_SINGLE_CONV;
  if (HAL_ADC_Init(&hadc2) != HAL_OK)
  {
    _Error_Handler(__FILE__, __LINE__);
  }

    /**Configure for the selected ADC regular channel its corresponding rank in the sequencer and its sample time.
    */
  sConfig.Channel = ADC_CHANNEL_4;
  sConfig.Rank = 1;
  sConfig.SamplingTime = ADC_SAMPLETIME_480CYCLES;
  if (HAL_ADC_ConfigChannel(&hadc2, &sConfig) != HAL_OK)
  {
    _Error_Handler(__FILE__, __LINE__);
  }

    /**Configure for the selected ADC regular channel its corresponding rank in the sequencer and its sample time.
    */
  sConfig.Rank = 2;
  sConfig.SamplingTime = ADC_SAMPLETIME_3CYCLES;
  if (HAL_ADC_ConfigChannel(&hadc2, &sConfig) != HAL_OK)
  {
    _Error_Handler(__FILE__, __LINE__);
  }

    /**Configure for the selected ADC regular channel its corresponding rank in the sequencer and its sample time.
    */
  sConfig.Rank = 3;
  if (HAL_ADC_ConfigChannel(&hadc2, &sConfig) != HAL_OK)
  {
    _Error_Handler(__FILE__, __LINE__);
  }

    /**Configure for the selected ADC regular channel its corresponding rank in the sequencer and its sample time.
    */
  sConfig.Rank = 4;
  if (HAL_ADC_ConfigChannel(&hadc2, &sConfig) != HAL_OK)
  {
    _Error_Handler(__FILE__, __LINE__);
  }

    /**Configure for the selected ADC regular channel its corresponding rank in the sequencer and its sample time.
    */
  sConfig.Channel = ADC_CHANNEL_6;
  sConfig.Rank = 2;
  sConfig.SamplingTime = ADC_SAMPLETIME_480CYCLES;
  if (HAL_ADC_ConfigChannel(&hadc2, &sConfig) != HAL_OK)
  {
    _Error_Handler(__FILE__, __LINE__);
  }

    /**Configure for the selected ADC regular channel its corresponding rank in the sequencer and its sample time.
    */
  sConfig.Channel = ADC_CHANNEL_7;
  sConfig.Rank = 3;
  if (HAL_ADC_ConfigChannel(&hadc2, &sConfig) != HAL_OK)
  {
    _Error_Handler(__FILE__, __LINE__);
  }

    /**Configure for the selected ADC regular channel its corresponding rank in the sequencer and its sample time.
    */
  sConfig.Channel = ADC_CHANNEL_14;
  sConfig.Rank = 4;
  if (HAL_ADC_ConfigChannel(&hadc2, &sConfig) != HAL_OK)
  {
    _Error_Handler(__FILE__, __LINE__);
  }

}

/* ADC3 init function */
static void MX_ADC3_Init(void)
{

  ADC_ChannelConfTypeDef sConfig;

    /**Configure the global features of the ADC (Clock, Resolution, Data Alignment and number of conversion)
    */
  hadc3.Instance = ADC3;
  hadc3.Init.ClockPrescaler = ADC_CLOCK_SYNC_PCLK_DIV8;
  hadc3.Init.Resolution = ADC_RESOLUTION_12B;
  hadc3.Init.ScanConvMode = ENABLE;
  hadc3.Init.ContinuousConvMode = DISABLE;
  hadc3.Init.DiscontinuousConvMode = DISABLE;
  hadc3.Init.ExternalTrigConvEdge = ADC_EXTERNALTRIGCONVEDGE_NONE;
  hadc3.Init.ExternalTrigConv = ADC_SOFTWARE_START;
  hadc3.Init.DataAlign = ADC_DATAALIGN_RIGHT;
  hadc3.Init.NbrOfConversion = 1;
  hadc3.Init.DMAContinuousRequests = ENABLE;
  hadc3.Init.EOCSelection = ADC_EOC_SINGLE_CONV;
  if (HAL_ADC_Init(&hadc3) != HAL_OK)
  {
    _Error_Handler(__FILE__, __LINE__);
  }

    /**Configure for the selected ADC regular channel its corresponding rank in the sequencer and its sample time.
    */
  sConfig.Channel = ADC_CHANNEL_13;
  sConfig.Rank = 1;
  sConfig.SamplingTime = ADC_SAMPLETIME_480CYCLES;
  if (HAL_ADC_ConfigChannel(&hadc3, &sConfig) != HAL_OK)
  {
    _Error_Handler(__FILE__, __LINE__);
  }

}

/* I2C1 init function */
static void MX_I2C1_Init(void)
{

  hi2c1.Instance = I2C1;
  hi2c1.Init.ClockSpeed = 100000;
  hi2c1.Init.DutyCycle = I2C_DUTYCYCLE_2;
  hi2c1.Init.OwnAddress1 = 0;
  hi2c1.Init.AddressingMode = I2C_ADDRESSINGMODE_7BIT;
  hi2c1.Init.DualAddressMode = I2C_DUALADDRESS_DISABLE;
  hi2c1.Init.OwnAddress2 = 0;
  hi2c1.Init.GeneralCallMode = I2C_GENERALCALL_DISABLE;
  hi2c1.Init.NoStretchMode = I2C_NOSTRETCH_DISABLE;
  if (HAL_I2C_Init(&hi2c1) != HAL_OK)
  {
    _Error_Handler(__FILE__, __LINE__);
  }

}

/* SPI2 init function */
static void MX_SPI2_Init(void)
{

  /* SPI2 parameter configuration*/
  hspi2.Instance = SPI2;
  hspi2.Init.Mode = SPI_MODE_SLAVE;
  hspi2.Init.Direction = SPI_DIRECTION_2LINES;
  hspi2.Init.DataSize = SPI_DATASIZE_8BIT;
  hspi2.Init.CLKPolarity = SPI_POLARITY_LOW;
  hspi2.Init.CLKPhase = SPI_PHASE_1EDGE;
  hspi2.Init.NSS = SPI_NSS_HARD_INPUT;
  hspi2.Init.FirstBit = SPI_FIRSTBIT_MSB;
  hspi2.Init.TIMode = SPI_TIMODE_DISABLE;
  hspi2.Init.CRCCalculation = SPI_CRCCALCULATION_DISABLE;
  hspi2.Init.CRCPolynomial = 10;
  if (HAL_SPI_Init(&hspi2) != HAL_OK)
  {
    _Error_Handler(__FILE__, __LINE__);
  }

}

/* SPI3 init function */
static void MX_SPI3_Init(void)
{

  /* SPI3 parameter configuration*/
  hspi3.Instance = SPI3;
  hspi3.Init.Mode = SPI_MODE_MASTER;
  hspi3.Init.Direction = SPI_DIRECTION_2LINES;
  hspi3.Init.DataSize = SPI_DATASIZE_8BIT;
  hspi3.Init.CLKPolarity = SPI_POLARITY_LOW;
  hspi3.Init.CLKPhase = SPI_PHASE_1EDGE;
  hspi3.Init.NSS = SPI_NSS_SOFT;
  hspi3.Init.BaudRatePrescaler = SPI_BAUDRATEPRESCALER_256;
  hspi3.Init.FirstBit = SPI_FIRSTBIT_MSB;
  hspi3.Init.TIMode = SPI_TIMODE_DISABLE;
  hspi3.Init.CRCCalculation = SPI_CRCCALCULATION_DISABLE;
  hspi3.Init.CRCPolynomial = 10;
  if (HAL_SPI_Init(&hspi3) != HAL_OK)
  {
    _Error_Handler(__FILE__, __LINE__);
  }

}

/* TIM1 init function */
static void MX_TIM1_Init(void)
{

  TIM_ClockConfigTypeDef sClockSourceConfig;
  TIM_MasterConfigTypeDef sMasterConfig;
  TIM_OC_InitTypeDef sConfigOC;
  TIM_BreakDeadTimeConfigTypeDef sBreakDeadTimeConfig;

  htim1.Instance = TIM1;
  htim1.Init.Prescaler = 60;
  htim1.Init.CounterMode = TIM_COUNTERMODE_DOWN;
  htim1.Init.Period = 60000;
  htim1.Init.ClockDivision = TIM_CLOCKDIVISION_DIV1;
  htim1.Init.RepetitionCounter = 0;
  if (HAL_TIM_Base_Init(&htim1) != HAL_OK)
  {
    _Error_Handler(__FILE__, __LINE__);
  }

  sClockSourceConfig.ClockSource = TIM_CLOCKSOURCE_INTERNAL;
  if (HAL_TIM_ConfigClockSource(&htim1, &sClockSourceConfig) != HAL_OK)
  {
    _Error_Handler(__FILE__, __LINE__);
  }

  if (HAL_TIM_PWM_Init(&htim1) != HAL_OK)
  {
    _Error_Handler(__FILE__, __LINE__);
  }

  sMasterConfig.MasterOutputTrigger = TIM_TRGO_RESET;
  sMasterConfig.MasterSlaveMode = TIM_MASTERSLAVEMODE_DISABLE;
  if (HAL_TIMEx_MasterConfigSynchronization(&htim1, &sMasterConfig) != HAL_OK)
  {
    _Error_Handler(__FILE__, __LINE__);
  }

  sConfigOC.OCMode = TIM_OCMODE_PWM1;
  sConfigOC.Pulse = 4180;
  sConfigOC.OCPolarity = TIM_OCPOLARITY_HIGH;
  sConfigOC.OCNPolarity = TIM_OCNPOLARITY_HIGH;
  sConfigOC.OCFastMode = TIM_OCFAST_DISABLE;
  sConfigOC.OCIdleState = TIM_OCIDLESTATE_RESET;
  sConfigOC.OCNIdleState = TIM_OCNIDLESTATE_RESET;
  if (HAL_TIM_PWM_ConfigChannel(&htim1, &sConfigOC, TIM_CHANNEL_1) != HAL_OK)
  {
    _Error_Handler(__FILE__, __LINE__);
  }

  if (HAL_TIM_PWM_ConfigChannel(&htim1, &sConfigOC, TIM_CHANNEL_4) != HAL_OK)
  {
    _Error_Handler(__FILE__, __LINE__);
  }

  sBreakDeadTimeConfig.OffStateRunMode = TIM_OSSR_DISABLE;
  sBreakDeadTimeConfig.OffStateIDLEMode = TIM_OSSI_DISABLE;
  sBreakDeadTimeConfig.LockLevel = TIM_LOCKLEVEL_OFF;
  sBreakDeadTimeConfig.DeadTime = 0;
  sBreakDeadTimeConfig.BreakState = TIM_BREAK_DISABLE;
  sBreakDeadTimeConfig.BreakPolarity = TIM_BREAKPOLARITY_HIGH;
  sBreakDeadTimeConfig.AutomaticOutput = TIM_AUTOMATICOUTPUT_DISABLE;
  if (HAL_TIMEx_ConfigBreakDeadTime(&htim1, &sBreakDeadTimeConfig) != HAL_OK)
  {
    _Error_Handler(__FILE__, __LINE__);
  }

  HAL_TIM_MspPostInit(&htim1);

}

/* TIM2 init function */
static void MX_TIM2_Init(void)
{

  TIM_Encoder_InitTypeDef sConfig;
  TIM_MasterConfigTypeDef sMasterConfig;

  htim2.Instance = TIM2;
  htim2.Init.Prescaler = 0;
  htim2.Init.CounterMode = TIM_COUNTERMODE_UP;
  htim2.Init.Period = 4294967295;
  htim2.Init.ClockDivision = TIM_CLOCKDIVISION_DIV1;
  sConfig.EncoderMode = TIM_ENCODERMODE_TI12;
  sConfig.IC1Polarity = TIM_ICPOLARITY_FALLING;
  sConfig.IC1Selection = TIM_ICSELECTION_DIRECTTI;
  sConfig.IC1Prescaler = TIM_ICPSC_DIV1;
  sConfig.IC1Filter = 0;
  sConfig.IC2Polarity = TIM_ICPOLARITY_RISING;
  sConfig.IC2Selection = TIM_ICSELECTION_DIRECTTI;
  sConfig.IC2Prescaler = TIM_ICPSC_DIV1;
  sConfig.IC2Filter = 0;
  if (HAL_TIM_Encoder_Init(&htim2, &sConfig) != HAL_OK)
  {
    _Error_Handler(__FILE__, __LINE__);
  }

  sMasterConfig.MasterOutputTrigger = TIM_TRGO_RESET;
  sMasterConfig.MasterSlaveMode = TIM_MASTERSLAVEMODE_DISABLE;
  if (HAL_TIMEx_MasterConfigSynchronization(&htim2, &sMasterConfig) != HAL_OK)
  {
    _Error_Handler(__FILE__, __LINE__);
  }

}

/* TIM3 init function */
static void MX_TIM3_Init(void)
{

  TIM_MasterConfigTypeDef sMasterConfig;
  TIM_OC_InitTypeDef sConfigOC;
  TIM_IC_InitTypeDef sConfigIC;

  htim3.Instance = TIM3;
  htim3.Init.Prescaler = 0;
  htim3.Init.CounterMode = TIM_COUNTERMODE_CENTERALIGNED1;
  htim3.Init.Period = 4500;
  htim3.Init.ClockDivision = TIM_CLOCKDIVISION_DIV1;
  if (HAL_TIM_PWM_Init(&htim3) != HAL_OK)
  {
    _Error_Handler(__FILE__, __LINE__);
  }

  if (HAL_TIM_IC_Init(&htim3) != HAL_OK)
  {
    _Error_Handler(__FILE__, __LINE__);
  }

  sMasterConfig.MasterOutputTrigger = TIM_TRGO_RESET;
  sMasterConfig.MasterSlaveMode = TIM_MASTERSLAVEMODE_DISABLE;
  if (HAL_TIMEx_MasterConfigSynchronization(&htim3, &sMasterConfig) != HAL_OK)
  {
    _Error_Handler(__FILE__, __LINE__);
  }

  sConfigOC.OCMode = TIM_OCMODE_PWM1;
  sConfigOC.Pulse = 2250;
  sConfigOC.OCPolarity = TIM_OCPOLARITY_HIGH;
  sConfigOC.OCFastMode = TIM_OCFAST_DISABLE;
  if (HAL_TIM_PWM_ConfigChannel(&htim3, &sConfigOC, TIM_CHANNEL_1) != HAL_OK)
  {
    _Error_Handler(__FILE__, __LINE__);
  }

  if (HAL_TIM_PWM_ConfigChannel(&htim3, &sConfigOC, TIM_CHANNEL_2) != HAL_OK)
  {
    _Error_Handler(__FILE__, __LINE__);
  }

  sConfigIC.ICPolarity = TIM_INPUTCHANNELPOLARITY_RISING;
  sConfigIC.ICSelection = TIM_ICSELECTION_DIRECTTI;
  sConfigIC.ICPrescaler = TIM_ICPSC_DIV1;
  sConfigIC.ICFilter = 0;
  if (HAL_TIM_IC_ConfigChannel(&htim3, &sConfigIC, TIM_CHANNEL_3) != HAL_OK)
  {
    _Error_Handler(__FILE__, __LINE__);
  }

  HAL_TIM_MspPostInit(&htim3);

}

/* TIM7 init function */
static void MX_TIM7_Init(void)
{

  TIM_MasterConfigTypeDef sMasterConfig;

  htim7.Instance = TIM7;
  htim7.Init.Prescaler = 0;
  htim7.Init.CounterMode = TIM_COUNTERMODE_UP;
  htim7.Init.Period = 0;
  if (HAL_TIM_Base_Init(&htim7) != HAL_OK)
  {
    _Error_Handler(__FILE__, __LINE__);
  }

  sMasterConfig.MasterOutputTrigger = TIM_TRGO_RESET;
  sMasterConfig.MasterSlaveMode = TIM_MASTERSLAVEMODE_DISABLE;
  if (HAL_TIMEx_MasterConfigSynchronization(&htim7, &sMasterConfig) != HAL_OK)
  {
    _Error_Handler(__FILE__, __LINE__);
  }

}

/* TIM10 init function */
static void MX_TIM10_Init(void)
{

  htim10.Instance = TIM10;
  htim10.Init.Prescaler = 0;
  htim10.Init.CounterMode = TIM_COUNTERMODE_UP;
  htim10.Init.Period = 0;
  htim10.Init.ClockDivision = TIM_CLOCKDIVISION_DIV1;
  if (HAL_TIM_Base_Init(&htim10) != HAL_OK)
  {
    _Error_Handler(__FILE__, __LINE__);
  }

}

/* TIM12 init function */
static void MX_TIM12_Init(void)
{

  TIM_SlaveConfigTypeDef sSlaveConfig;
  TIM_IC_InitTypeDef sConfigIC;

  htim12.Instance = TIM12;
  htim12.Init.Prescaler = 100;
  htim12.Init.CounterMode = TIM_COUNTERMODE_UP;
  htim12.Init.Period = 65535;
  htim12.Init.ClockDivision = TIM_CLOCKDIVISION_DIV1;
  if (HAL_TIM_IC_Init(&htim12) != HAL_OK)
  {
    _Error_Handler(__FILE__, __LINE__);
  }

  sSlaveConfig.SlaveMode = TIM_SLAVEMODE_RESET;
  sSlaveConfig.InputTrigger = TIM_TS_TI1FP1;
  sSlaveConfig.TriggerPolarity = TIM_INPUTCHANNELPOLARITY_RISING;
  sSlaveConfig.TriggerPrescaler = TIM_ICPSC_DIV1;
  sSlaveConfig.TriggerFilter = 0;
  if (HAL_TIM_SlaveConfigSynchronization(&htim12, &sSlaveConfig) != HAL_OK)
  {
    _Error_Handler(__FILE__, __LINE__);
  }

  sConfigIC.ICPolarity = TIM_INPUTCHANNELPOLARITY_RISING;
  sConfigIC.ICSelection = TIM_ICSELECTION_DIRECTTI;
  sConfigIC.ICPrescaler = TIM_ICPSC_DIV1;
  sConfigIC.ICFilter = 0;
  if (HAL_TIM_IC_ConfigChannel(&htim12, &sConfigIC, TIM_CHANNEL_1) != HAL_OK)
  {
    _Error_Handler(__FILE__, __LINE__);
  }

  sConfigIC.ICPolarity = TIM_INPUTCHANNELPOLARITY_FALLING;
  sConfigIC.ICSelection = TIM_ICSELECTION_INDIRECTTI;
  if (HAL_TIM_IC_ConfigChannel(&htim12, &sConfigIC, TIM_CHANNEL_2) != HAL_OK)
  {
    _Error_Handler(__FILE__, __LINE__);
  }

}

/* UART4 init function */
static void MX_UART4_Init(void)
{

  huart4.Instance = UART4;
  huart4.Init.BaudRate = 9600;
  huart4.Init.WordLength = UART_WORDLENGTH_8B;
  huart4.Init.StopBits = UART_STOPBITS_1;
  huart4.Init.Parity = UART_PARITY_NONE;
  huart4.Init.Mode = UART_MODE_TX_RX;
  huart4.Init.HwFlowCtl = UART_HWCONTROL_NONE;
  huart4.Init.OverSampling = UART_OVERSAMPLING_16;
  if (HAL_UART_Init(&huart4) != HAL_OK)
  {
    _Error_Handler(__FILE__, __LINE__);
  }

}

/* USART1 init function */
static void MX_USART1_UART_Init(void)
{

  huart1.Instance = USART1;
  huart1.Init.BaudRate = 921600;
  huart1.Init.WordLength = UART_WORDLENGTH_8B;
  huart1.Init.StopBits = UART_STOPBITS_1;
  huart1.Init.Parity = UART_PARITY_NONE;
  huart1.Init.Mode = UART_MODE_TX_RX;
  huart1.Init.HwFlowCtl = UART_HWCONTROL_NONE;
  huart1.Init.OverSampling = UART_OVERSAMPLING_16;
  if (HAL_UART_Init(&huart1) != HAL_OK)
  {
    _Error_Handler(__FILE__, __LINE__);
  }

}

/* USART2 init function */
static void MX_USART2_UART_Init(void)
{

  huart2.Instance = USART2;
  huart2.Init.BaudRate = 115200;
  huart2.Init.WordLength = UART_WORDLENGTH_8B;
  huart2.Init.StopBits = UART_STOPBITS_1;
  huart2.Init.Parity = UART_PARITY_NONE;
  huart2.Init.Mode = UART_MODE_TX_RX;
  huart2.Init.HwFlowCtl = UART_HWCONTROL_NONE;
  huart2.Init.OverSampling = UART_OVERSAMPLING_16;
  if (HAL_UART_Init(&huart2) != HAL_OK)
  {
    _Error_Handler(__FILE__, __LINE__);
  }

}

static void MX_DMA_Init(void)
{
  /* DMA controller clock enable */
  __HAL_RCC_DMA2_CLK_ENABLE();
  __HAL_RCC_DMA1_CLK_ENABLE();

  /* DMA interrupt init */
  /* DMA1_Stream0_IRQn interrupt configuration */
  HAL_NVIC_SetPriority(DMA1_Stream0_IRQn, 5, 0);
  HAL_NVIC_EnableIRQ(DMA1_Stream0_IRQn);
  /* DMA1_Stream2_IRQn interrupt configuration */
  HAL_NVIC_SetPriority(DMA1_Stream2_IRQn, 5, 0);
  HAL_NVIC_EnableIRQ(DMA1_Stream2_IRQn);
  /* DMA1_Stream3_IRQn interrupt configuration */
  HAL_NVIC_SetPriority(DMA1_Stream3_IRQn, 5, 0);
  HAL_NVIC_EnableIRQ(DMA1_Stream3_IRQn);
  /* DMA1_Stream4_IRQn interrupt configuration */
  HAL_NVIC_SetPriority(DMA1_Stream4_IRQn, 5, 0);
  HAL_NVIC_EnableIRQ(DMA1_Stream4_IRQn);
  /* DMA1_Stream5_IRQn interrupt configuration */
  HAL_NVIC_SetPriority(DMA1_Stream5_IRQn, 5, 0);
  HAL_NVIC_EnableIRQ(DMA1_Stream5_IRQn);
  /* DMA1_Stream6_IRQn interrupt configuration */
  HAL_NVIC_SetPriority(DMA1_Stream6_IRQn, 5, 0);
  HAL_NVIC_EnableIRQ(DMA1_Stream6_IRQn);
  /* DMA1_Stream7_IRQn interrupt configuration */
  HAL_NVIC_SetPriority(DMA1_Stream7_IRQn, 5, 0);
  HAL_NVIC_EnableIRQ(DMA1_Stream7_IRQn);
  /* DMA2_Stream0_IRQn interrupt configuration */
  HAL_NVIC_SetPriority(DMA2_Stream0_IRQn, 5, 0);
  HAL_NVIC_EnableIRQ(DMA2_Stream0_IRQn);
  /* DMA2_Stream1_IRQn interrupt configuration */
  HAL_NVIC_SetPriority(DMA2_Stream1_IRQn, 5, 0);
  HAL_NVIC_EnableIRQ(DMA2_Stream1_IRQn);
  /* DMA2_Stream2_IRQn interrupt configuration */
  HAL_NVIC_SetPriority(DMA2_Stream2_IRQn, 5, 0);
  HAL_NVIC_EnableIRQ(DMA2_Stream2_IRQn);
  /* DMA2_Stream3_IRQn interrupt configuration */
  HAL_NVIC_SetPriority(DMA2_Stream3_IRQn, 5, 0);
  HAL_NVIC_EnableIRQ(DMA2_Stream3_IRQn);
  /* DMA2_Stream5_IRQn interrupt configuration */
  HAL_NVIC_SetPriority(DMA2_Stream5_IRQn, 5, 0);
  HAL_NVIC_EnableIRQ(DMA2_Stream5_IRQn);
  /* DMA2_Stream7_IRQn interrupt configuration */
  HAL_NVIC_SetPriority(DMA2_Stream7_IRQn, 5, 0);
  HAL_NVIC_EnableIRQ(DMA2_Stream7_IRQn);

}

/** Configure pins as
        * Analog
        * Input
        * Output
        * EVENT_OUT
        * EXTI
*/
static void MX_GPIO_Init(void)
{

  GPIO_InitTypeDef GPIO_InitStruct;

  /* GPIO Ports Clock Enable */
  __HAL_RCC_GPIOC_CLK_ENABLE();
  __HAL_RCC_GPIOH_CLK_ENABLE();
  __HAL_RCC_GPIOA_CLK_ENABLE();
  __HAL_RCC_GPIOB_CLK_ENABLE();
  __HAL_RCC_GPIOD_CLK_ENABLE();

  /*Configure GPIO pin Output Level */
  HAL_GPIO_WritePin(LD2_GPIO_Port, LD2_Pin, GPIO_PIN_RESET);

  /*Configure GPIO pin Output Level */
  HAL_GPIO_WritePin(VonalGetData_GPIO_Port, VonalGetData_Pin, GPIO_PIN_RESET);

  /*Configure GPIO pin Output Level */
  HAL_GPIO_WritePin(Vonal_NSS_GPIO_Port, Vonal_NSS_Pin, GPIO_PIN_SET);

  /*Configure GPIO pin : B1_Pin */
  GPIO_InitStruct.Pin = B1_Pin;
  GPIO_InitStruct.Mode = GPIO_MODE_IT_FALLING;
  GPIO_InitStruct.Pull = GPIO_NOPULL;
  HAL_GPIO_Init(B1_GPIO_Port, &GPIO_InitStruct);

  /*Configure GPIO pin : LD2_Pin */
  GPIO_InitStruct.Pin = LD2_Pin;
  GPIO_InitStruct.Mode = GPIO_MODE_OUTPUT_PP;
  GPIO_InitStruct.Pull = GPIO_NOPULL;
  GPIO_InitStruct.Speed = GPIO_SPEED_FREQ_LOW;
  HAL_GPIO_Init(LD2_GPIO_Port, &GPIO_InitStruct);

  /*Configure GPIO pin : VonalGetData_Pin */
  GPIO_InitStruct.Pin = VonalGetData_Pin;
  GPIO_InitStruct.Mode = GPIO_MODE_OUTPUT_PP;
  GPIO_InitStruct.Pull = GPIO_NOPULL;
  GPIO_InitStruct.Speed = GPIO_SPEED_FREQ_LOW;
  HAL_GPIO_Init(VonalGetData_GPIO_Port, &GPIO_InitStruct);

  /*Configure GPIO pin : PB10 */
  GPIO_InitStruct.Pin = GPIO_PIN_10;
  GPIO_InitStruct.Mode = GPIO_MODE_IT_RISING;
  GPIO_InitStruct.Pull = GPIO_NOPULL;
  HAL_GPIO_Init(GPIOB, &GPIO_InitStruct);

  /*Configure GPIO pin : Vonal_NSS_Pin */
  GPIO_InitStruct.Pin = Vonal_NSS_Pin;
  GPIO_InitStruct.Mode = GPIO_MODE_OUTPUT_PP;
  GPIO_InitStruct.Pull = GPIO_NOPULL;
  GPIO_InitStruct.Speed = GPIO_SPEED_FREQ_VERY_HIGH;
  HAL_GPIO_Init(Vonal_NSS_GPIO_Port, &GPIO_InitStruct);

  /*Configure GPIO pin : PD2 */
  GPIO_InitStruct.Pin = GPIO_PIN_2;
  GPIO_InitStruct.Mode = GPIO_MODE_IT_RISING;
  GPIO_InitStruct.Pull = GPIO_NOPULL;
  HAL_GPIO_Init(GPIOD, &GPIO_InitStruct);

  /* EXTI interrupt init*/
  HAL_NVIC_SetPriority(EXTI2_IRQn, 5, 0);
  HAL_NVIC_EnableIRQ(EXTI2_IRQn);

  HAL_NVIC_SetPriority(EXTI15_10_IRQn, 5, 0);
  HAL_NVIC_EnableIRQ(EXTI15_10_IRQn);

}

/* USER CODE BEGIN 4 */
void TimerCallback(TimerHandle_t xTimer )
{

	/* Optionally do something if the pxTimer parameter is NULL. */
	configASSERT( xTimer );

	uint32_t timID =  ( uint32_t ) pvTimerGetTimerID( xTimer );

	CarCounterTimerElapsedFlag = 1;
}

void InitTimers()
{
 /* Create then start some timers.  Starting the timers before
	 the RTOS scheduler has been started means the timers will start
	 running immediately that the RTOS scheduler starts. */
	 for( int x = 0; x < NUM_OF_TIMERS; x++ )
	 {
		 xTimers[x] = xTimerCreate
		   ( /* Just a text name, not used by the RTOS
			 kernel. */
			 "Timer",
			 /* The timer period in ticks, must be
			 greater than 0. */
			 5000,
			 /* The timers will auto-reload themselves
			 when they expire. */
			 pdFALSE,
			 /* The ID is used to store a count of the
			 number of times the timer has expired, which
			 is initialised to 0. */
			 ( void * ) 0,
			 /* Each timer calls the same callback when
			 it expires. */
			 TimerCallback
		   );

		 if( xTimers[ x ] == NULL )
		 {
			 /* The timer was not created. */
		 }
		 else
		 {
			 /* Start the timer.  No block time is specified, and
			 even if one was it would be ignored because the RTOS
			 scheduler has not yet been started. */
			 if( xTimerStart( xTimers[ x ], 0 ) != pdPASS )
			 {
				 /* The timer could not be set into the Active
				 state. */
			 }
		 }
	 }
}

void SetTasks(){
	if(Mode == UGYESSEGI)
	{
		osThreadResume(RemotecontrolTaskHandle);
		osThreadResume(ReadDistanceSensorsTaskHandle);
		osThreadResume(ReadMotorCurrentTaskHandle);
		osThreadResume(InfraReceiveTaskHandle);
		//osThreadResume(ReadMEMSTaskHandle);
		osThreadResume(StateMachineTaskHandle);
	}
	else if( Mode == GYORSASAGI )
	{
		osThreadSuspend(RemotecontrolTaskHandle);
		osThreadSuspend(ReadDistanceSensorsTaskHandle);
		osThreadSuspend(ReadMotorCurrentTaskHandle);
		osThreadSuspend(InfraReceiveTaskHandle);
		//osThreadSuspend(ReadMEMSTaskHandle);
		osThreadSuspend(StateMachineTaskHandle);
	}
	else if( Mode == SLAVE)
	{
		osThreadSuspend(RemotecontrolTaskHandle);
		osThreadSuspend(ReadDistanceSensorsTaskHandle);
		osThreadSuspend(ReadMotorCurrentTaskHandle);
		osThreadSuspend(InfraReceiveTaskHandle);
		//osThreadSuspend(ReadMEMSTaskHandle);
		osThreadSuspend(StateMachineTaskHandle);
	}

}

void InitTask(void const * argument)
{
	while(1)
	{
		Semaphore_ADC_batteries = xSemaphoreCreateBinary();
		Semaphore_linesensor_ready = xSemaphoreCreateBinary();
		Semaphore_SPI_vonal_buffer = xSemaphoreCreateBinary();
		Semaphore_ADC_dist_sensors = xSemaphoreCreateBinary();
		Semaphore_ADC_motor_curr = xSemaphoreCreateBinary();
		Semaphore_MEMS_ready = xSemaphoreCreateBinary();
		Semaphore_Uthossz_Achieved  = xSemaphoreCreateBinary();
		Eventgroup_inputCaptures = xEventGroupCreate();
		Eventgroup_Triggers = xEventGroupCreate();

		BluetoothInit(&huart1);
		LineInit(&hspi3);
		HAL_TIM_PWM_Start(&htim1, TIM_CHANNEL_1);
		HAL_TIM_PWM_Start(&htim3, TIM_CHANNEL_1);
		HAL_TIM_PWM_Start(&htim3, TIM_CHANNEL_2);
		HAL_TIM_PWM_Start(&htim1, TIM_CHANNEL_4);
		HAL_TIM_Encoder_Start_IT(&htim2, TIM_CHANNEL_ALL);
		//HAL_TIM_IC_Start(&htim4 , TIM_CHANNEL_1);	//RC-PWM fogadása
		//HAL_TIM_IC_Start_IT(&htim4, TIM_CHANNEL_2);		//RC-PWM fogadása
		HAL_TIM_IC_Start(&htim12 , TIM_CHANNEL_1);	//RC-PWM fogadása
		HAL_TIM_IC_Start_IT(&htim12, TIM_CHANNEL_2);		//RC-PWM fogadása
		//HAL_TIM_IC_Start_IT(&htim8, TIM_CHANNEL_3);
		osDelay(500);
		osThreadResume(LineDataTaskHandle);
		osThreadResume(SendBTTaskHandle);
		//osThreadResume(DetectTaskHandle);
		osThreadResume(defaultTaskHandle);
		//osThreadResume(RemotecontrolTaskHandle);
		//osThreadResume(CheckBatteriesTaskHandle);
		osThreadResume(ReadDistanceSensorsTaskHandle);
		//osThreadResume(ReadMotorCurrentTaskHandle);
		//osThreadResume(InfraReceiveTaskHandle);
		//osThreadResume(ReadMEMSTaskHandle);
		osThreadResume(SpeedControllerTaskHandle);
		osThreadResume(UthosszTaskHandle);
		//osThreadResume(SteeringStateSpaceControllerHandle);
		osThreadResume(ServoSetterTaskHandle);
		//osThreadResume(LineDetectorTaskHandle);
		//osThreadResume(StateMachineTaskHandle);
		//osThreadResume(ControllerTaskHandle);
		//osThreadResume(CarTrackerTaskHandle);
		osThreadResume(HMITaskHandle);
		BluetoothReceive();
		HMIReceive();
		//StarterInit();
		RpiListen();
		//SetTasks();
		osThreadTerminate(NULL);
	}
	osThreadTerminate(NULL);
}

/* USER CODE END 4 */

/* StartDefaultTask function */
void StartDefaultTask(void const * argument)
{

  /* USER CODE BEGIN 5 */
  /* Infinite loop */
  for(;;)
  {
    HAL_GPIO_TogglePin(LD2_GPIO_Port, LD2_Pin);		//three short
    osDelay(150);
  }
  osThreadTerminate(NULL);
  /* USER CODE END 5 */
}

void _Error_Handler(char * file, int line)
{
  while(1)
  {
  }
}

/************************ (C) COPYRIGHT STMicroelectronics *****END OF FILE****/
